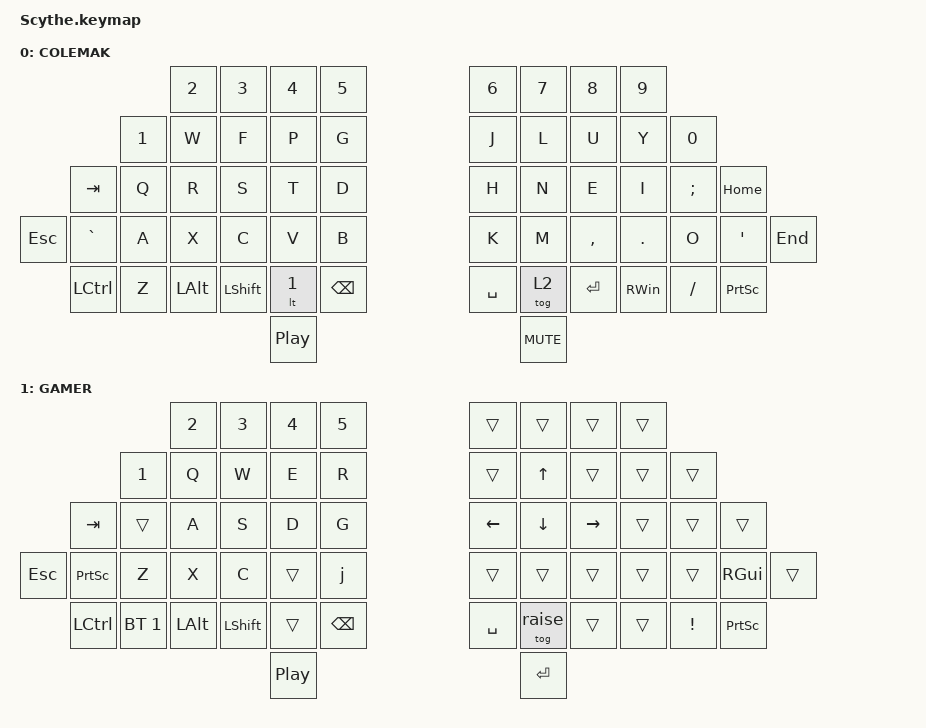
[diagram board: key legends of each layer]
/*
 * Copyright (c) 2020 The ZMK Contributors
 *
 * SPDX-License-Identifier: MIT
 */

#include <behaviors.dtsi>
include <dt-bindings/zmk/keys.h>
include <dt-bindings/zmk/bt.h>
#include <dt-bindings/zmk/rgb.h>
#include <dt-bindings/zmk/ext_power.h>

#define Colemak (base) 0
#define MATHS 1
#define RAISE 2
#define GAMER (WASD) 3

/ {

   // Activate ADJUST layer by pressing raise and lower
    conditional_layers {
        compatible = "zmk,conditional-layers";
        adjust_layer {
            if-layers = <LOWER RAISE>;
            then-layer = <ADJUST>;
        };
    };

    keymap {
        compatible = "zmk,keymap";

        default_layer {
            display-name = "COLEMAK";

// SCYTHE KEYMAP Colemak                                                                                  
               bindings = <
//                                _________ _________ _________ _________                          _________ _________ _________ _________
//                               |    2    |    3    |    4    |    5    |                        |    6    |    7    |    8    |    9    |
                                    &kp N2   &kp N3   &kp N4    &kp N5                             &kp N6     &kp N7   &kp N8    &kp N9
//                      _________ _________ _________ _________ _________                          _________ _________ _________ _________ _________
//                     |    1    |    W    |    F    |    P    |    G    |                        |    J    |    L    |    U    |    Y    |    0    |    
                          &kp N1    &kp W    &kp F    &kp P     &kp G                              &kp J      &kp L    &kp U     &kp Y      &kp N0
//            _________ _________ _________ _________ _________ _________                          _________ _________ _________ _________ _________ _________
//           |   tab   |    Q    |    R    |    S    |    T    |    D    |                        |    H    |    N    |    E    |    I    |    ;    |  home   |
              &kp TAB     &kp Q     &kp R    &kp S    &kp T     &kp D                              &kp H      &kp N    &kp E     &kp I      &kp SEMI &kp HOME
//  _________ _________ _________ _________ _________ _________ _________                          _________ _________ _________ _________ _________ _________ _________
// |   esc   |    ~`   |    A    |    X    |    C    |    V    |    B    |                        |    K    |    M    |    <,   |   .>    |   O    |    "    |   end   | 
     &kp ESC  &kp GRAVE   &kp A     &kp X    &kp C    &kp V     &kp B                              &kp K      &kp M    &kp COMMA &kp PERIOD &kp O    &kp SQT    &kp END
//  --------- _________ _________ --------- _________ _________ _________ _________|    |_________ _________ _________ _________ _________ _________ _________ ---------
//           |  Lctrl  |    z    |         |   Alt   |  Shift  |  Lower  |  BCKSPC |    |  space  |  Raise  |  ENTER  |   WIN   |         |    /?   |  PRINT  |
              &kp LCTRL   &kp Z              &kp LALT &kp LSHFT &lt 1     &kp BSPC      &kp SPACE  &tog 2     &kp RET  &kp RWIN             &kp FSLH &kp PSCRN
//            --------- ----------          --------- _________ --------- ---------|    |--------- --------- _________ ---------           --------- ---------
//                                                   |  Scrll  |                                            |   vol   |
                                                      &kp C_PP                                                &kp C_MUTE      
//                                                            
>;
            sensor-bindings = <&inc_dec_kp C_VOL_DN C_VOL_UP &inc_dec_kp PG_DN PG_UP>;
        };

        lower_layer {
            display-name = "MATH";
// SCYTHE KEYMAP MATHS 
               bindings = <
//                                _________ _________ _________ _________                          _________ _________ _________ _________
//                               |   F2    |    #    |    $    |    %    |                        |    &    |    {    |    }    |    [    |                            
                                   &kp F2    &kp HASH &kp DLLR  &kp PRCNT                          &kp AMPS   &kp LBRC &kp RBRC  &kp LBKT
//                      _________ _________ _________ _________ _________                          _________ _________ _________ _________ _________
//                     |    F1   |    P    |    UP   |    /    |    ^    |                        |   DEL   |    7    |    8    |    9    |    ]    |          
                         &kp F1    &kp P     &kp UP   &kp FSLH  &kp CARET                          &kp DLT    &kp N7   &kp N8    &kp N9     &kp RBKT
//            _________ _________ _________ _________ _________ _________                          _________ _________ _________ _________ _________ _________
//           |   tab   |    =    |   Left  |   down  |  right  |    E    |                        |    *    |    4    |    5    |    6    |    <    |    >    |        
              &kp TAB    &kp EQUAL &kp LEFT  &kp DOWN &kp RIGHT &kp E                              &kp ASTRK  &kp N4   &kp N5    &kp N6     &kp LT   &kp GT
//  _________ _________ _________ _________ _________ _________ _________                          _________ _________ _________ _________ _________ _________ _________
// |   esc   |   \|\   |    (     |   HOME  |   END   |    .    |    -    |                        |    +    |    1    |    2    |    3    |    )   |    :    |    ;    | 
     &kp ESC  &kp NUBS   &kp LPAR  &kp HOME  &kp END  &kp DOT   &kp MINUS                          &kp PLUS   &kp N1   &kp N2    &kp N3     &kp RPAR &kp COLON &kp SEMI         
//  --------- _________ _________ --------- _________ _________ _________ _________|    |_________ _________ _________ _________ _________ _________ _________ ---------
//           |  Lctrl  |    $    |         |   Alt   |  Shift  |  Lower  |  BKSPC  |    |  SPACE  |  Raise  |    0    |   DLT   |         |    !    |  PRINT  |
              &kp LCTRL  &kp Z               &kp LALT &kp LSHFT &lt 1     &kp BSPC      &kp SPACE  &tog raise &kp N0   &kp DLT              &kp EXCL &kp PSCRN
//            --------- ----------          --------- _________ --------- ---------|    |--------- --------- _________ ---------           --------- ---------
//                                                   |  Scrll  |                                            |  ENTER  |
                                                      &kp C_PP                                                &kp RET      
//
>;
            sensor-bindings = <&inc_dec_kp C_VOL_DN C_VOL_UP &inc_dec_kp PG_DN PG_UP>;
        };
 lower_layer {
            display-name = "GAMER";
// SCYTHE KEYMAP MATHS 
               bindings = <
//                                _________ _________ _________ _________                          _________ _________ _________ _________
//                               |    2    |    3    |    4    |    5    |                        |         |         |         |         |                            
                                   &kp 2     &kp 3    &kp 4     &kp 5                              &trans     &trans   &trans    &trans
//                      _________ _________ _________ _________ _________                          _________ _________ _________ _________ _________
//                     |     1   |    Q    |    W   |    E    |    R    |                        |          |    up    |        |         |         |          
                         &kp 1     &kp Q     &kp W    &kp E     &kp R                              &trans     &kp UP   &trans    &trans     &trans
//            _________ _________ _________ _________ _________ _________                          _________ _________ _________ _________ _________ _________
//           |   tab   |         |    A    |    S    |    D    |    G    |                        |    left |    down  |  right |         |         |         |        
              &kp TAB    &trans    &kp A     &kp S    &kp D     &kp G                              &kp LEFT   &kp DOWN &kp RIGHT &trans     &trans   &trans
//  _________ _________ _________ _________ _________ _________ _________                          _________ _________ _________ _________ _________ _________ _________
// |   esc   |   PRNT   |    Z     |    X   |    C    |         |    J    |                        |         |         |         |         |        |         |         | 
     &kp ESC  &kp PSCRN  &kp Z     &kp X     &kp C    &trans    &kp j                              &trans     &trans   &trans    &trans     &trans   &kp RGUI    &trans        
//  --------- _________ _________ --------- _________ _________ _________ _________|    |_________ _________ _________ _________ _________ _________ _________ ---------
//           |  Lctrl  |   BT1   |         |   Alt   |  Shift  |  Lower  |  BKSPC  |    |  SPACE  |  Raise  |         |   DLT   |         |    !    |  PRINT  |
              &kp LCTRL  &bt BT_SEL 1        &kp LALT &kp LSHFT &trans    &kp BSPC      &kp SPACE  &tog raise &trans   &trans               &kp EXCL &kp PSCRN
//            --------- ----------          --------- _________ --------- ---------|    |--------- --------- _________ ---------           --------- ---------
//                                                   |  Scrll  |                                            |  ENTER  |
                                                      &kp C_PP                                                &kp RET      
//
>;
            sensor-bindings = <&inc_dec_kp C_VOL_DN C_VOL_UP &inc_dec_kp PG_DN PG_UP>;
        };
